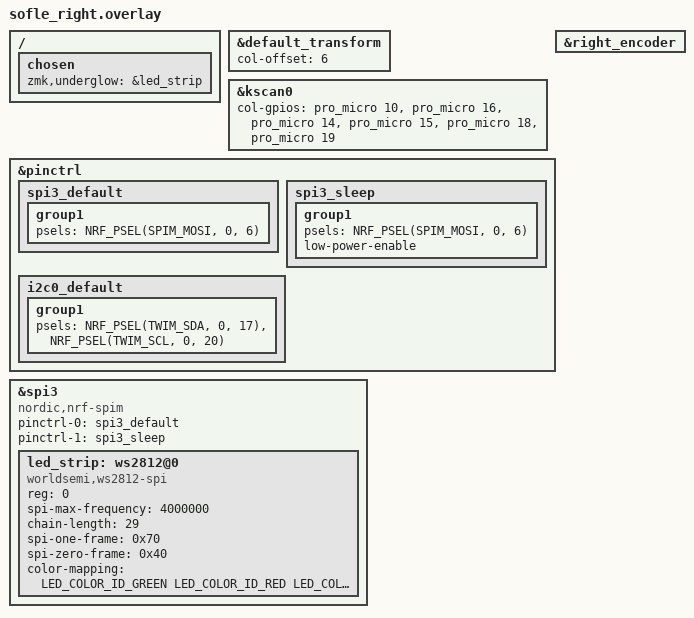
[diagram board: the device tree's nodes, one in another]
#include "sofle.dtsi"
#include <dt-bindings/led/led.h>

&default_transform {
    col-offset = <6>;
};

&kscan0 {
    col-gpios
        = <&pro_micro 10 GPIO_ACTIVE_HIGH>
        , <&pro_micro 16 GPIO_ACTIVE_HIGH>
        , <&pro_micro 14 GPIO_ACTIVE_HIGH>
        , <&pro_micro 15 GPIO_ACTIVE_HIGH>
        , <&pro_micro 18 GPIO_ACTIVE_HIGH>
        , <&pro_micro 19 GPIO_ACTIVE_HIGH>
        ;
};

&right_encoder {
    status = "okay";
};

&pinctrl {
    spi3_default: spi3_default {
        group1 {
            psels = <NRF_PSEL(SPIM_MOSI, 0, 6)>;
        };
    };
    spi3_sleep: spi3_sleep {
        group1 {
            psels = <NRF_PSEL(SPIM_MOSI, 0, 6)>;
            low-power-enable;
        };
    };
    i2c0_default: i2c0_default {
        group1 {
            psels = <NRF_PSEL(TWIM_SDA, 0, 17)>, <NRF_PSEL(TWIM_SCL, 0, 20)>;
        };
    };
};

&spi3 {
    compatible = "nordic,nrf-spim";
    status = "okay";
    pinctrl-0 = <&spi3_default>;
    pinctrl-1 = <&spi3_sleep>;
    pinctrl-names = "default", "sleep";

    led_strip: ws2812@0 {
        compatible = "worldsemi,ws2812-spi";
        reg = <0>;
        spi-max-frequency = <4000000>;
        chain-length = <29>;
        spi-one-frame = <0x70>;
        spi-zero-frame = <0x40>;
        color-mapping = <LED_COLOR_ID_GREEN LED_COLOR_ID_RED LED_COLOR_ID_BLUE>;
    };
};

/*
&i2c0 {
    status = "okay";
    compatible = "nordic,nrf-twim";
    pinctrl-0 = <&i2c0_default>;
    pinctrl-names = "default";
    clock-frequency = <I2C_BITRATE_FAST>;

    touchpad: touchpad@15 {
        compatible = "zmk,input-i2c-hid";
        reg = <0x15>;
        irq-gpios = <&gpio1 7 (GPIO_ACTIVE_LOW | GPIO_PULL_UP)>;
    };
};

&gpio1 {
    touchpad_rst {
        gpio-hog;
        gpios = <2 GPIO_ACTIVE_HIGH>;
        output-high;
        line-name = "Touchpad Reset";
    };
};
*/

/ {
    chosen {
        zmk,underglow = &led_strip;
    };
};
// vim: filetype=dts fdm=marker:
